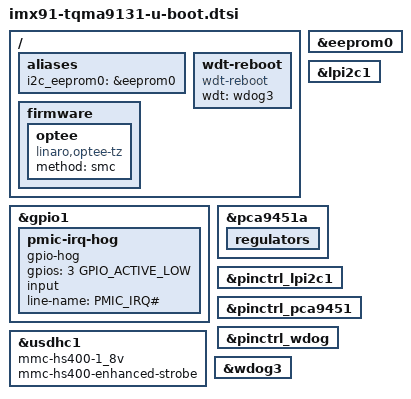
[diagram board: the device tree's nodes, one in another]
// SPDX-License-Identifier: (GPL-2.0-or-later OR MIT)
/*
 * Copyright (c) 2024 TQ-Systems GmbH <u-boot@ew.tq-group.com>,
 * D-82229 Seefeld, Germany.
 * Author: Markus Niebel
 */

/*
 * include the generic, CPU specific part of U-Boot modifications
 * for device tree
 */
#include "imx91-u-boot.dtsi"

/ {
	aliases {
		i2c_eeprom0 = &eeprom0;
	};

	wdt-reboot {
		compatible = "wdt-reboot";
		wdt = <&wdog3>;
		bootph-pre-ram;
		bootph-some-ram;
	};

	firmware {
		optee {
			compatible = "linaro,optee-tz";
			method = "smc";
		};
	};
};

&eeprom0 {
	bootph-pre-ram;
	/delete-property/ read-only;
	/delete-property/ vcc-supply;
};

&gpio1 {
	bootph-pre-ram;

	pmic-irq-hog {
		gpio-hog;
		gpios = <3 GPIO_ACTIVE_LOW>;
		input;
		line-name = "PMIC_IRQ#";
	};
};

&lpi2c1 {
	bootph-pre-ram;
};

&pca9451a {
	bootph-pre-ram;

	regulators {
		bootph-pre-ram;
	};
};

&pinctrl_lpi2c1 {
	bootph-pre-ram;
};

&pinctrl_pca9451 {
	bootph-pre-ram;
};

&pinctrl_wdog {
	bootph-pre-ram;
	bootph-some-ram;
};

&usdhc1 {
	mmc-hs400-1_8v;
	mmc-hs400-enhanced-strobe;
	/*
	 * prevents voltage switch warn: driver will switch even at
	 * fixed voltage
	 */
	/delete-property/ vmmc-supply;
	/delete-property/ vqmmc-supply;
};

&wdog3 {
	bootph-pre-ram;
	bootph-some-ram;
};
